# WKUP_CTRL_MMR_WKUP_CTRL_MMR_CFG0_43000000h register map
Vendor: Texas Instruments
Peripheral module from a debugger description file (folder am62D).
Registers are 32-bit, read-write, reset 0x0 unless marked. A register's access mark holds for its fields unless they carry their own. Offsets are as the file gives them; lines under a group give offsets from that group; [hi:lo] are bit positions; {n}, {i} and the like mark numbered series; 'fields as' and 'values as' point back to an identical list; <NAME> marks a mode.

## WKUP_CTRL_MMR_CFG0 (part 1 of 3)
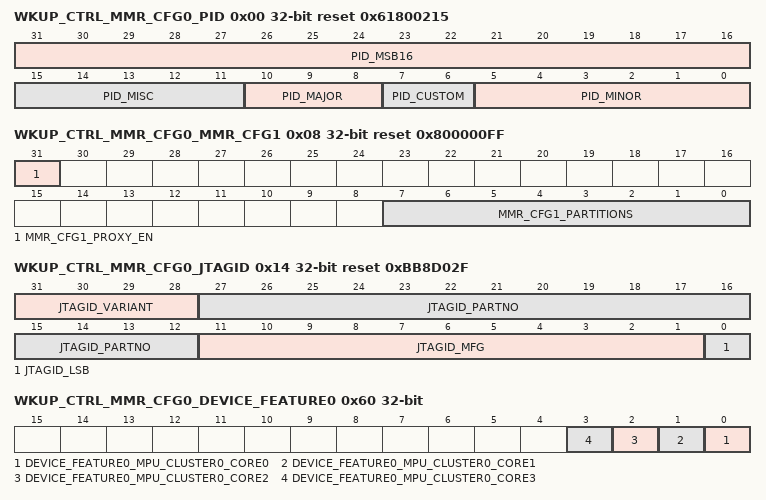
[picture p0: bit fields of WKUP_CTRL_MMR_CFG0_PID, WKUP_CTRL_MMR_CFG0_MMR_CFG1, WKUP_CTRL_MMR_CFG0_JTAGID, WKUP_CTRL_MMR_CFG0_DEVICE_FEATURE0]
0x00 WKUP_CTRL_MMR_CFG0_PID ro reset 0x61800215
  [31:16] PID_MSB16 — Reset Source: mod_g_rst_n
  [15:11] PID_MISC — Reset Source: mod_g_rst_n
  [10:8] PID_MAJOR — Reset Source: mod_g_rst_n
  [7:6] PID_CUSTOM — Reset Source: mod_g_rst_n
  [5:0] PID_MINOR — Reset Source: mod_g_rst_n
0x08 WKUP_CTRL_MMR_CFG0_MMR_CFG1 ro reset 0x800000FF
  [31] MMR_CFG1_PROXY_EN — Proxy addressing activated Reset Source: mod_por_rst_n
  [7:0] MMR_CFG1_PARTITIONS — Indicates present partitions Reset Source: mod_por_rst_n
0x14 WKUP_CTRL_MMR_CFG0_JTAGID ro reset 0xBB8D02F
  [31:28] JTAGID_VARIANT — Used to indicate new PGs Reset Source: mod_por_rst_n
  [27:12] JTAGID_PARTNO — Part number for boundary scan Reset Source: mod_por_rst_n
  [11:1] JTAGID_MFG — Indicates manufacturer Reset Source: mod_por_rst_n
  [0] JTAGID_LSB — Always 1 Reset Source: mod_por_rst_n
0x18 WKUP_CTRL_MMR_CFG0_JTAG_USER_ID ro
  [31:0] JTAG_USER_ID_USERCODE — Device information Reset Source: mod_por_rst_n
0x30 WKUP_CTRL_MMR_CFG0_MAIN_DEVSTAT
  [15:0] MAIN_DEVSTAT_BOOTMODE — Specifies the device Primary and Backup boot media. Reset Source: mod_por_rst_n
0x34 WKUP_CTRL_MMR_CFG0_MAIN_BOOTCFG ro
  [15:0] MAIN_BOOTCFG_BOOTMODE — Specifies the device Primary and Backup boot media as latched at PORz Reset Source: mod_por_rst_n
0x44 WKUP_CTRL_MMR_CFG0_BOOT_PROGRESS
  [31:0] BOOT_PROGRESS_PROGRESS — Written by ROM to indicate boot progression. Values and their meaning are determined by the ROM. Reset Source: mod_por_rst_n
0x60 WKUP_CTRL_MMR_CFG0_DEVICE_FEATURE0 ro
  [n] DEVICE_FEATURE0_MPU_CLUSTER0_CORE{n} (n=0..3) — MPU Cluster0 Core {n} is activated when set Reset Source: mod_por_rst_n
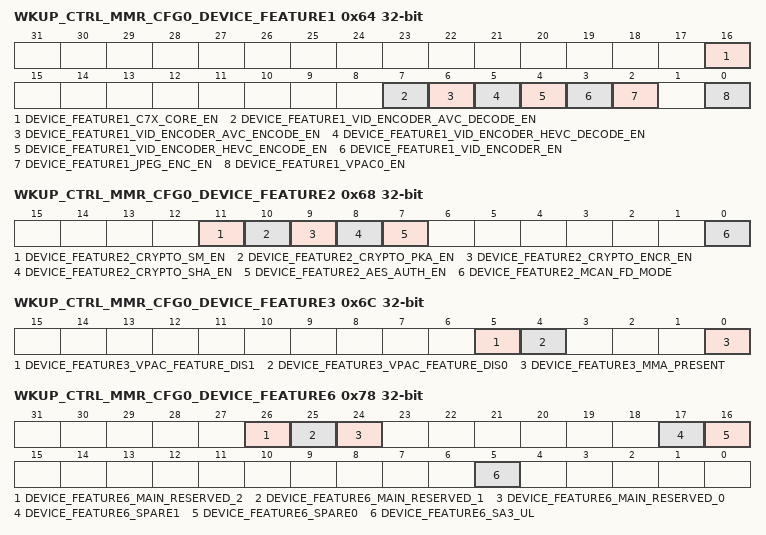
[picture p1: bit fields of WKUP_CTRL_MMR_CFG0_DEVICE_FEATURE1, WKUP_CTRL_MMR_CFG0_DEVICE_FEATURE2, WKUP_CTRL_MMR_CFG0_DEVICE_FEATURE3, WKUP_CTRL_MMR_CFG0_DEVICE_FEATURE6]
0x64 WKUP_CTRL_MMR_CFG0_DEVICE_FEATURE1 ro
  [16] DEVICE_FEATURE1_C7X_CORE_EN — C7x is activated when set Reset Source: mod_por_rst_n
  [7] DEVICE_FEATURE1_VID_ENCODER_AVC_DECODE_EN — Video CODEC HEVC decode feature activated when set Reset Source: mod_por_rst_n
  [6] DEVICE_FEATURE1_VID_ENCODER_AVC_ENCODE_EN — Video CODEC HEVC encode feature activated when set Reset Source: mod_por_rst_n
  [5] DEVICE_FEATURE1_VID_ENCODER_HEVC_DECODE_EN — Video CODEC AVC decode feature activated when set Reset Source: mod_por_rst_n
  [4] DEVICE_FEATURE1_VID_ENCODER_HEVC_ENCODE_EN — Video CODEC AVC encode feature activated when set Reset Source: mod_por_rst_n
  [3] DEVICE_FEATURE1_VID_ENCODER_EN — Video CODEC is activated when set Reset Source: mod_por_rst_n
  [2] DEVICE_FEATURE1_JPEG_ENC_EN — JPEG Encoder is activated when set Reset Source: mod_por_rst_n
  [0] DEVICE_FEATURE1_VPAC0_EN — VPAC0 is activated when set Reset Source: mod_por_rst_n
0x68 WKUP_CTRL_MMR_CFG0_DEVICE_FEATURE2 ro
  [11] DEVICE_FEATURE2_CRYPTO_SM_EN — SA3SS Crypto Module SM2, SM3, SM4 activated Reset Source: mod_por_rst_n
  [10] DEVICE_FEATURE2_CRYPTO_PKA_EN — SA3SS Crypto Module PKA activated Reset Source: mod_por_rst_n
  [9] DEVICE_FEATURE2_CRYPTO_ENCR_EN — SA3SS Crypto Module AES/3DES/DBRG activated Reset Source: mod_por_rst_n
  [8] DEVICE_FEATURE2_CRYPTO_SHA_EN — SA3SS Crypto Module SHA/MD5 activated Reset Source: mod_por_rst_n
  [7] DEVICE_FEATURE2_AES_AUTH_EN — AES authentication is activated in FlashSS and SMS when set Reset Source: mod_por_rst_n
  [0] DEVICE_FEATURE2_MCAN_FD_MODE — FD mode is supported on all MCAN when set Reset Source: mod_por_rst_n
0x6C WKUP_CTRL_MMR_CFG0_DEVICE_FEATURE3 ro
  [5] DEVICE_FEATURE3_VPAC_FEATURE_DIS1 — VPAC Feature 1 Deactivated When Set Reset Source: mod_por_rst_n
  [4] DEVICE_FEATURE3_VPAC_FEATURE_DIS0 — VPAC Feature 0 DIsabled When Set Reset Source: mod_por_rst_n
  [0] DEVICE_FEATURE3_MMA_PRESENT — C7x MMA Present when Set Reset Source: mod_por_rst_n
0x78 WKUP_CTRL_MMR_CFG0_DEVICE_FEATURE6 ro
  [26] DEVICE_FEATURE6_MAIN_RESERVED_2 — Main Domain Reserved 2 LPSC is activated when set
  [25] DEVICE_FEATURE6_MAIN_RESERVED_1 — Main Domain Reserved 1 LPSC is activated when set
  [24] DEVICE_FEATURE6_MAIN_RESERVED_0 — Main Domain Reserved 0 LPSC is activated when set
  [17] DEVICE_FEATURE6_SPARE1 — Spare1 LPSC is activated when set Reset Source: mod_por_rst_n
  [16] DEVICE_FEATURE6_SPARE0 — Spare0 LPSC is activated when set Reset Source: mod_por_rst_n
  [5] DEVICE_FEATURE6_SA3_UL — SA3SS domain security accelerator is activated when set Reset Source: mod_por_rst_n
0x200 WKUP_CTRL_MMR_CFG0_MAC_ID0
  [31:0] MAC_ID0_MACID_LO — 32 lsbs of MAC address Reset Source: mod_g_rst_n
0x204 WKUP_CTRL_MMR_CFG0_MAC_ID1
  [15:0] MAC_ID1_MACID_HI — 16 msbs of MAC address Reset Source: mod_g_rst_n
0x220 WKUP_CTRL_MMR_CFG0_USB_DEVICE_ID0 reset 0x61650451
  [31:0] USB_DEVICE_ID0_ID0 — ROM writes 32-bit Value from Customer OTP to Here Reset Source: mod_g_rst_n
0x224 WKUP_CTRL_MMR_CFG0_USB_DEVICE_ID1 reset 0x61650451
  [31:0] USB_DEVICE_ID1_ID1 — ROM writes 32-bit Value from Customer OTP to Here Reset Source: mod_g_rst_n
{0x230+4i} WKUP_CTRL_MMR_CFG0_GP_SW{i} ro (i=0..2)
  [31:0] GP_SW{i}_VAL — general purpose value Reset Source: mod_por_rst_n
0x23C WKUP_CTRL_MMR_CFG0_GP_SW3 ro
  [3:0] GP_SW3_VAL — general purpose value Reset Source: mod_por_rst_n
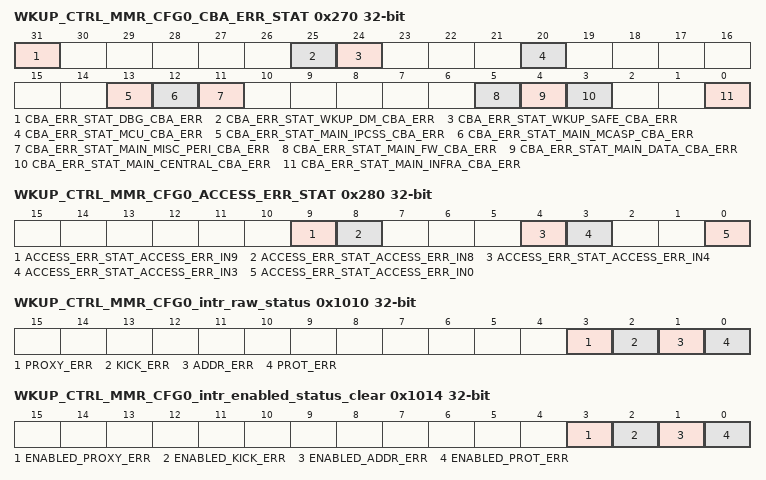
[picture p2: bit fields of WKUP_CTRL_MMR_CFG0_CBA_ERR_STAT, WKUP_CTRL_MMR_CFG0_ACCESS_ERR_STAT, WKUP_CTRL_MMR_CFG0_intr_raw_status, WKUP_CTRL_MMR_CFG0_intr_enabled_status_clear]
0x270 WKUP_CTRL_MMR_CFG0_CBA_ERR_STAT ro
  [31] CBA_ERR_STAT_DBG_CBA_ERR — Access Error from Main Debug CBASS Reset Source: mod_g_rst_n
  [25] CBA_ERR_STAT_WKUP_DM_CBA_ERR — Access Error from Wkup Device Manager CBASS Reset Source: mod_g_rst_n
  [24] CBA_ERR_STAT_WKUP_SAFE_CBA_ERR — Access Error from Wkup Safe CBASS Reset Source: mod_g_rst_n
  [20] CBA_ERR_STAT_MCU_CBA_ERR — Access Error from MCU CBASS Reset Source: mod_g_rst_n
  [13] CBA_ERR_STAT_MAIN_IPCSS_CBA_ERR — Access Error from Main IPCSS CBASS Reset Source: mod_g_rst_n
  [12] CBA_ERR_STAT_MAIN_MCASP_CBA_ERR — Access Error from Main McASP CBASS Reset Source: mod_g_rst_n
  [11] CBA_ERR_STAT_MAIN_MISC_PERI_CBA_ERR — Access Errror from Main Misc. Peripheral CBASS Reset Source: mod_g_rst_n
  [5] CBA_ERR_STAT_MAIN_FW_CBA_ERR — Access Error from Main Firewall CBASS Reset Source: mod_g_rst_n
  [4] CBA_ERR_STAT_MAIN_DATA_CBA_ERR — Access Error from Main Data CBASS Reset Source: mod_g_rst_n
  [3] CBA_ERR_STAT_MAIN_CENTRAL_CBA_ERR — Access Error from Main Central CBASS Reset Source: mod_g_rst_n
  [0] CBA_ERR_STAT_MAIN_INFRA_CBA_ERR — Access Error from Main Infrastructure CBASS Reset Source: mod_g_rst_n
0x280 WKUP_CTRL_MMR_CFG0_ACCESS_ERR_STAT ro
  [9] ACCESS_ERR_STAT_ACCESS_ERR_IN9 — Access Error Detected in MCU PadCfg MMR Reset Source: mod_por_rst_n
  [8] ACCESS_ERR_STAT_ACCESS_ERR_IN8 — Access Error Detected in MCU Ctrl MMR Reset Source: mod_por_rst_n
  [4] ACCESS_ERR_STAT_ACCESS_ERR_IN4 — Access Error Detected in MAIN PadCfg MMR Reset Source: mod_por_rst_n
  [3] ACCESS_ERR_STAT_ACCESS_ERR_IN3 — Access Error Detected in MAIN Ctrl MMR Reset Source: mod_por_rst_n
  [0] ACCESS_ERR_STAT_ACCESS_ERR_IN0 — Access Error Detected in WKUP Ctrl MMR Reset Source: mod_por_rst_n
{0x1008+0x4000*i} WKUP_CTRL_MMR_CFG0_LOCK{i}_KICK0 (i=0..7)
  [31:0] LOCK{i}_KICK0 — - KICK0 component Reset Source: mod_g_rst_n
{0x100C+0x4000*i} WKUP_CTRL_MMR_CFG0_LOCK{i}_KICK1 (i=0..7)
  [31:0] LOCK{i}_KICK1 — - KICK1 component Reset Source: mod_g_rst_n
0x1010 WKUP_CTRL_MMR_CFG0_intr_raw_status access not given
  [3] PROXY_ERR — Proxy0 access violation error. Raw status is read. Write a 1 to set the status. Writing a 0 has no effect. Reset Source: mod_g_rst_n (access R/W1TS)
  [2] KICK_ERR — Kick access violation error. Raw status is read. Write a 1 to set the status. Writing a 0 has no effect. Reset Source: mod_g_rst_n (access R/W1TS)
  [1] ADDR_ERR — Addressing violation error. Raw status is read. Write a 1 to set the status. Writing a 0 has no effect. Reset Source: mod_g_rst_n (access R/W1TS)
  [0] PROT_ERR — Protection violation error. Raw status is read. Write a 1 to set the status. Writing a 0 has no effect. Reset Source: mod_g_rst_n (access R/W1TS)
0x1014 WKUP_CTRL_MMR_CFG0_intr_enabled_status_clear access not given
  [3] ENABLED_PROXY_ERR — Proxy0 access violation error. Enabled status is read. Write a 1 to clear the status. Writing a 0 has no effect. Reset Source: mod_g_rst_n (access R/W1TC)
  [2] ENABLED_KICK_ERR — Kick access violation error. Enabled status is read. Write a 1 to clear the status. Writing a 0 has no effect. Reset Source: mod_g_rst_n (access R/W1TC)
  [1] ENABLED_ADDR_ERR — Addressing violation error. Enabled status is read. Write a 1 to clear the status. Writing a 0 has no effect. Reset Source: mod_g_rst_n (access R/W1TC)
  [0] ENABLED_PROT_ERR — Protection violation error. Enabled status is read. Write a 1 to clear the status. Writing a 0 has no effect. Reset Source: mod_g_rst_n (access R/W1TC)
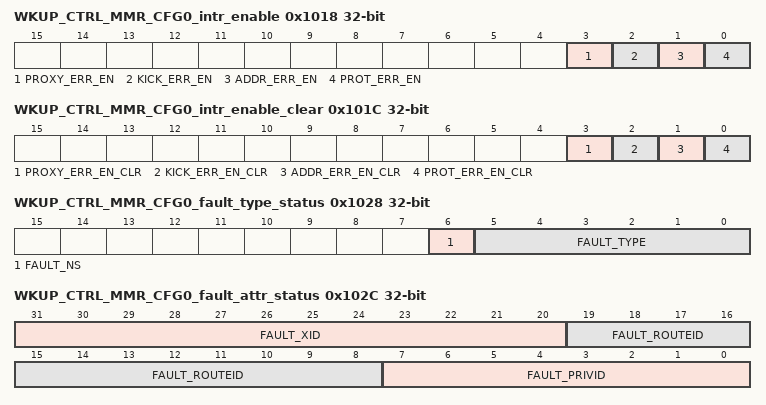
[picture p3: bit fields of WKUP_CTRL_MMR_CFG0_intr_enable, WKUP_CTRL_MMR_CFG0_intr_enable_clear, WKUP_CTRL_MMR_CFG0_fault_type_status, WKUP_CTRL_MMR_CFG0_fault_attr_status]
0x1018 WKUP_CTRL_MMR_CFG0_intr_enable access not given
  [3] PROXY_ERR_EN — Proxy0 access violation error enable. Write a 1 to set the enable. Writing a 0 has no effect. Reset Source: mod_g_rst_n (access R/W1TS)
  [2] KICK_ERR_EN — Kick access violation error enable. Write a 1 to set the enable. Writing a 0 has no effect. Reset Source: mod_g_rst_n (access R/W1TS)
  [1] ADDR_ERR_EN — Addressing violation error enable. Write a 1 to set the enable. Writing a 0 has no effect. Reset Source: mod_g_rst_n (access R/W1TS)
  [0] PROT_ERR_EN — Protection violation error enable. Write a 1 to set the enable. Writing a 0 has no effect. Reset Source: mod_g_rst_n (access R/W1TS)
0x101C WKUP_CTRL_MMR_CFG0_intr_enable_clear access not given
  [3] PROXY_ERR_EN_CLR — Proxy0 access violation error enable clear. Write a 1 to clear the enable. Writing a 0 has no effect. Reset Source: mod_g_rst_n (access R/W1TC)
  [2] KICK_ERR_EN_CLR — Kick access violation error enable clear. Write a 1 to clear the enable. Writing a 0 has no effect. Reset Source: mod_g_rst_n (access R/W1TC)
  [1] ADDR_ERR_EN_CLR — Addressing violation error enable clear. Write a 1 to clear the enable. Writing a 0 has no effect. Reset Source: mod_g_rst_n (access R/W1TC)
  [0] PROT_ERR_EN_CLR — Protection violation error enable clear. Write a 1 to clear the enable. Writing a 0 has no effect. Reset Source: mod_g_rst_n (access R/W1TC)
0x1020 WKUP_CTRL_MMR_CFG0_eoi
  [7:0] EOI_VECTOR — EOI vector value. Write this with interrupt distribution value in the chip. Reset Source: mod_g_rst_n
0x1024 WKUP_CTRL_MMR_CFG0_fault_address ro
  [31:0] FAULT_ADDR — Fault Address. Reset Source: mod_g_rst_n
0x1028 WKUP_CTRL_MMR_CFG0_fault_type_status ro
  [6] FAULT_NS — Non-secure access. Reset Source: mod_g_rst_n
  [5:0] FAULT_TYPE — Fault Type 10_0000 = Supervisor read fault - priv = 1 dir = 1 dtype != 1 01_0000 = Supervisor write fault - priv = 1 dir = 0 00_1000 = Supervisor execute fault - priv = 1 dir = 1 dtype = 1 00_0100 = User read fault - priv = 0 dir = 1 dtype = 1 00_0010 = User write fault - priv = 0 dir = 0 00_0001 = User execute fault - priv = 0 dir = 1 dtype = 1 00_0000 = No fault Reset Source: mod_g_rst_n
0x102C WKUP_CTRL_MMR_CFG0_fault_attr_status ro
  [31:20] FAULT_XID — XID. Reset Source: mod_g_rst_n
  [19:8] FAULT_ROUTEID — Route ID. Reset Source: mod_g_rst_n
  [7:0] FAULT_PRIVID — Privilege ID. Reset Source: mod_g_rst_n
0x1030 WKUP_CTRL_MMR_CFG0_fault_clear wo
  [0] FAULT_CLR — Fault clear. Writing a 1 clears the current fault. Writing a 0 has no effect. Reset Source: mod_g_rst_n
{0x1100+4i} WKUP_CTRL_MMR_CFG0_CLAIMREG_P0_R{i}_READONLY ro (i=0..6)
  [31:0] CLAIMREG_P0_R{i}_READONLY — Claim bits for Partition 0 Reset Source: mod_g_rst_n
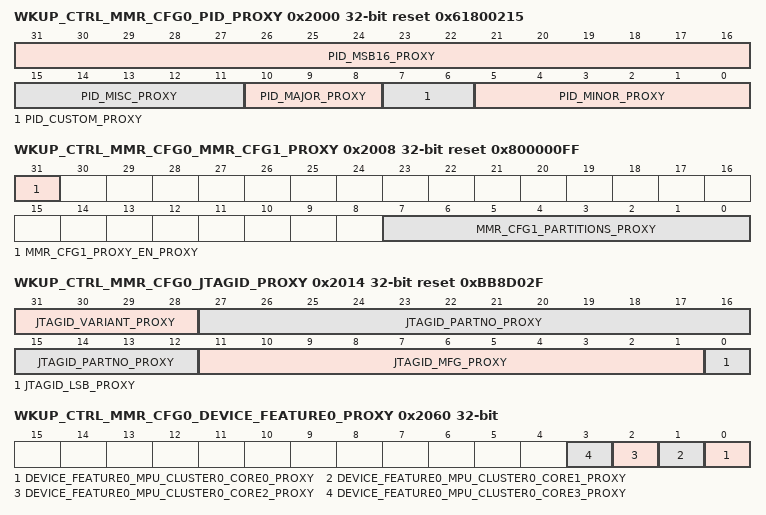
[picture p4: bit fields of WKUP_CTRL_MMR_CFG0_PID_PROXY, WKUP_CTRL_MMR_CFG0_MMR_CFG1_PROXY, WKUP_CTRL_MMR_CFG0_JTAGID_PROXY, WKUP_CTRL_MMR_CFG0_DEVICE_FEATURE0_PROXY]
0x2000 WKUP_CTRL_MMR_CFG0_PID_PROXY ro reset 0x61800215
  [31:16] PID_MSB16_PROXY — Reset Source: mod_g_rst_n
  [15:11] PID_MISC_PROXY — Reset Source: mod_g_rst_n
  [10:8] PID_MAJOR_PROXY — Reset Source: mod_g_rst_n
  [7:6] PID_CUSTOM_PROXY — Reset Source: mod_g_rst_n
  [5:0] PID_MINOR_PROXY — Reset Source: mod_g_rst_n
0x2008 WKUP_CTRL_MMR_CFG0_MMR_CFG1_PROXY ro reset 0x800000FF
  [31] MMR_CFG1_PROXY_EN_PROXY — Proxy addressing activated Reset Source: mod_por_rst_n
  [7:0] MMR_CFG1_PARTITIONS_PROXY — Indicates present partitions Reset Source: mod_por_rst_n
0x2014 WKUP_CTRL_MMR_CFG0_JTAGID_PROXY ro reset 0xBB8D02F
  [31:28] JTAGID_VARIANT_PROXY — Used to indicate new PGs Reset Source: mod_por_rst_n
  [27:12] JTAGID_PARTNO_PROXY — Part number for boundary scan Reset Source: mod_por_rst_n
  [11:1] JTAGID_MFG_PROXY — Indicates manufacturer Reset Source: mod_por_rst_n
  [0] JTAGID_LSB_PROXY — Always 1 Reset Source: mod_por_rst_n
0x2018 WKUP_CTRL_MMR_CFG0_JTAG_USER_ID_PROXY ro
  [31:0] JTAG_USER_ID_USERCODE_PROXY — Device information Reset Source: mod_por_rst_n
0x2030 WKUP_CTRL_MMR_CFG0_MAIN_DEVSTAT_PROXY
  [15:0] MAIN_DEVSTAT_BOOTMODE_PROXY — Specifies the device Primary and Backup boot media. Reset Source: mod_por_rst_n
0x2034 WKUP_CTRL_MMR_CFG0_MAIN_BOOTCFG_PROXY ro
  [15:0] MAIN_BOOTCFG_BOOTMODE_PROXY — Specifies the device Primary and Backup boot media as latched at PORz Reset Source: mod_por_rst_n
0x2044 WKUP_CTRL_MMR_CFG0_BOOT_PROGRESS_PROXY
  [31:0] BOOT_PROGRESS_PROGRESS_PROXY — Written by ROM to indicate boot progression. Values and their meaning are determined by the ROM. Reset Source: mod_por_rst_n
0x2060 WKUP_CTRL_MMR_CFG0_DEVICE_FEATURE0_PROXY ro
  [n] DEVICE_FEATURE0_MPU_CLUSTER0_CORE{n}_PROXY (n=0..3) — MPU Cluster0 Core {n} is activated when set Reset Source: mod_por_rst_n
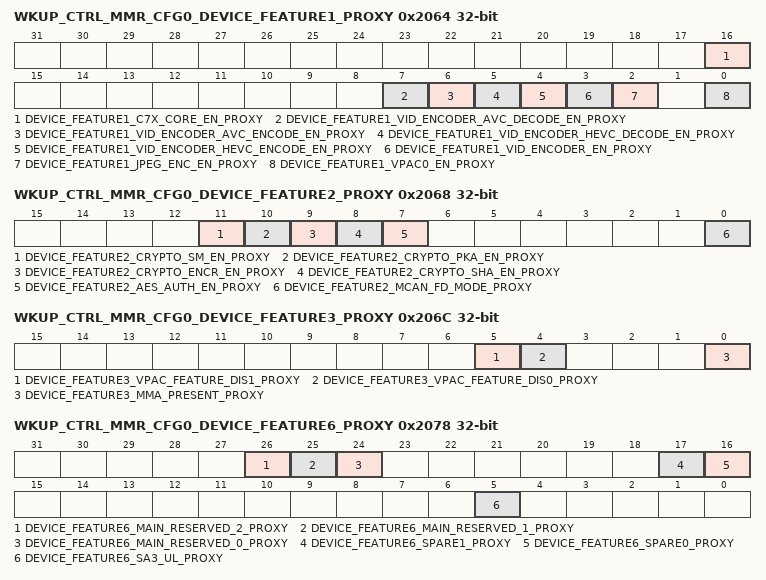
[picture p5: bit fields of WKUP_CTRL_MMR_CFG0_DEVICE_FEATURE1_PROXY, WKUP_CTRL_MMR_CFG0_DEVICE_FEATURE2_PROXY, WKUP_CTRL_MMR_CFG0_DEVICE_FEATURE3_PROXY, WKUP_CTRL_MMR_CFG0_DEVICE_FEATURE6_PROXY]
0x2064 WKUP_CTRL_MMR_CFG0_DEVICE_FEATURE1_PROXY ro
  [16] DEVICE_FEATURE1_C7X_CORE_EN_PROXY — C7x is activated when set Reset Source: mod_por_rst_n
  [7] DEVICE_FEATURE1_VID_ENCODER_AVC_DECODE_EN_PROXY — Video CODEC HEVC decode feature activated when set Reset Source: mod_por_rst_n
  [6] DEVICE_FEATURE1_VID_ENCODER_AVC_ENCODE_EN_PROXY — Video CODEC HEVC encode feature activated when set Reset Source: mod_por_rst_n
  [5] DEVICE_FEATURE1_VID_ENCODER_HEVC_DECODE_EN_PROXY — Video CODEC AVC decode feature activated when set Reset Source: mod_por_rst_n
  [4] DEVICE_FEATURE1_VID_ENCODER_HEVC_ENCODE_EN_PROXY — Video CODEC AVC encode feature activated when set Reset Source: mod_por_rst_n
  [3] DEVICE_FEATURE1_VID_ENCODER_EN_PROXY — Video CODEC is activated when set Reset Source: mod_por_rst_n
  [2] DEVICE_FEATURE1_JPEG_ENC_EN_PROXY — JPEG Encoder is activated when set Reset Source: mod_por_rst_n
  [0] DEVICE_FEATURE1_VPAC0_EN_PROXY — VPAC0 is activated when set Reset Source: mod_por_rst_n
0x2068 WKUP_CTRL_MMR_CFG0_DEVICE_FEATURE2_PROXY ro
  [11] DEVICE_FEATURE2_CRYPTO_SM_EN_PROXY — SA3SS Crypto Module SM2, SM3, SM4 activated Reset Source: mod_por_rst_n
  [10] DEVICE_FEATURE2_CRYPTO_PKA_EN_PROXY — SA3SS Crypto Module PKA activated Reset Source: mod_por_rst_n
  [9] DEVICE_FEATURE2_CRYPTO_ENCR_EN_PROXY — SA3SS Crypto Module AES/3DES/DBRG activated Reset Source: mod_por_rst_n
  [8] DEVICE_FEATURE2_CRYPTO_SHA_EN_PROXY — SA3SS Crypto Module SHA/MD5 activated Reset Source: mod_por_rst_n
  [7] DEVICE_FEATURE2_AES_AUTH_EN_PROXY — AES authentication is activated in FlashSS and SMS when set Reset Source: mod_por_rst_n
  [0] DEVICE_FEATURE2_MCAN_FD_MODE_PROXY — FD mode is supported on all MCAN when set Reset Source: mod_por_rst_n
0x206C WKUP_CTRL_MMR_CFG0_DEVICE_FEATURE3_PROXY ro
  [5] DEVICE_FEATURE3_VPAC_FEATURE_DIS1_PROXY — VPAC Feature 1 Deactivated When Set Reset Source: mod_por_rst_n
  [4] DEVICE_FEATURE3_VPAC_FEATURE_DIS0_PROXY — VPAC Feature 0 DIsabled When Set Reset Source: mod_por_rst_n
  [0] DEVICE_FEATURE3_MMA_PRESENT_PROXY — C7x MMA Present when Set Reset Source: mod_por_rst_n
0x2078 WKUP_CTRL_MMR_CFG0_DEVICE_FEATURE6_PROXY ro
  [26] DEVICE_FEATURE6_MAIN_RESERVED_2_PROXY — Main Domain Reserved 2 LPSC is activated when set
  [25] DEVICE_FEATURE6_MAIN_RESERVED_1_PROXY — Main Domain Reserved 1 LPSC is activated when set
  [24] DEVICE_FEATURE6_MAIN_RESERVED_0_PROXY — Main Domain Reserved 0 LPSC is activated when set
  [17] DEVICE_FEATURE6_SPARE1_PROXY — Spare1 LPSC is activated when set Reset Source: mod_por_rst_n
  [16] DEVICE_FEATURE6_SPARE0_PROXY — Spare0 LPSC is activated when set Reset Source: mod_por_rst_n
  [5] DEVICE_FEATURE6_SA3_UL_PROXY — SA3SS domain security accelerator is activated when set Reset Source: mod_por_rst_n
0x2200 WKUP_CTRL_MMR_CFG0_MAC_ID0_PROXY
  [31:0] MAC_ID0_MACID_LO_PROXY — 32 lsbs of MAC address Reset Source: mod_g_rst_n
0x2204 WKUP_CTRL_MMR_CFG0_MAC_ID1_PROXY
  [15:0] MAC_ID1_MACID_HI_PROXY — 16 msbs of MAC address Reset Source: mod_g_rst_n
0x2220 WKUP_CTRL_MMR_CFG0_USB_DEVICE_ID0_PROXY reset 0x61650451
  [31:0] USB_DEVICE_ID0_ID0_PROXY — ROM writes 32-bit Value from Customer OTP to Here Reset Source: mod_g_rst_n
0x2224 WKUP_CTRL_MMR_CFG0_USB_DEVICE_ID1_PROXY reset 0x61650451
  [31:0] USB_DEVICE_ID1_ID1_PROXY — ROM writes 32-bit Value from Customer OTP to Here Reset Source: mod_g_rst_n
{0x2230+4i} WKUP_CTRL_MMR_CFG0_GP_SW{i}_PROXY ro (i=0..2)
  [31:0] GP_SW{i}_VAL_PROXY — general purpose value Reset Source: mod_por_rst_n
0x223C WKUP_CTRL_MMR_CFG0_GP_SW3_PROXY ro
  [3:0] GP_SW3_VAL_PROXY — general purpose value Reset Source: mod_por_rst_n
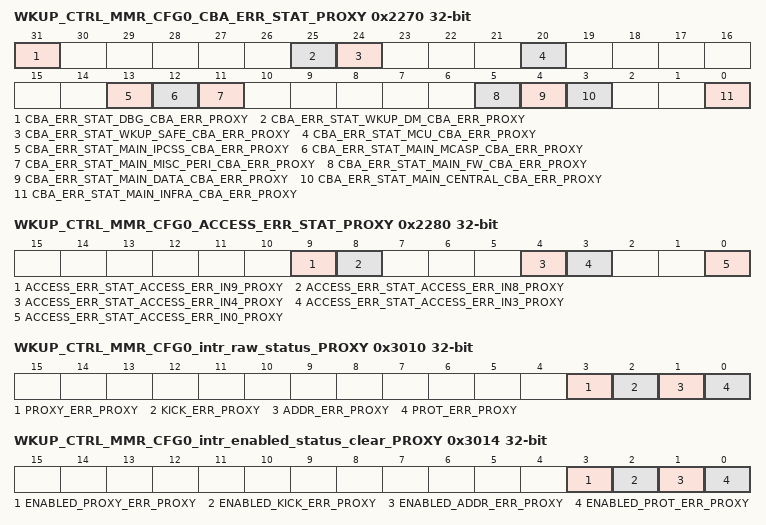
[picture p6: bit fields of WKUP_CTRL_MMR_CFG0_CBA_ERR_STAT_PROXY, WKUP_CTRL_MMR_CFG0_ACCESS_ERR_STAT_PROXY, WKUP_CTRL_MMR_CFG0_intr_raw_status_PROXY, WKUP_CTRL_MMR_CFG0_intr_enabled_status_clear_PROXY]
0x2270 WKUP_CTRL_MMR_CFG0_CBA_ERR_STAT_PROXY ro
  [31] CBA_ERR_STAT_DBG_CBA_ERR_PROXY — Access Error from Main Debug CBASS Reset Source: mod_g_rst_n
  [25] CBA_ERR_STAT_WKUP_DM_CBA_ERR_PROXY — Access Error from Wkup Device Manager CBASS Reset Source: mod_g_rst_n
  [24] CBA_ERR_STAT_WKUP_SAFE_CBA_ERR_PROXY — Access Error from Wkup Safe CBASS Reset Source: mod_g_rst_n
  [20] CBA_ERR_STAT_MCU_CBA_ERR_PROXY — Access Error from MCU CBASS Reset Source: mod_g_rst_n
  [13] CBA_ERR_STAT_MAIN_IPCSS_CBA_ERR_PROXY — Access Error from Main IPCSS CBASS Reset Source: mod_g_rst_n
  [12] CBA_ERR_STAT_MAIN_MCASP_CBA_ERR_PROXY — Access Error from Main McASP CBASS Reset Source: mod_g_rst_n
  [11] CBA_ERR_STAT_MAIN_MISC_PERI_CBA_ERR_PROXY — Access Errror from Main Misc. Peripheral CBASS Reset Source: mod_g_rst_n
  [5] CBA_ERR_STAT_MAIN_FW_CBA_ERR_PROXY — Access Error from Main Firewall CBASS Reset Source: mod_g_rst_n
  [4] CBA_ERR_STAT_MAIN_DATA_CBA_ERR_PROXY — Access Error from Main Data CBASS Reset Source: mod_g_rst_n
  [3] CBA_ERR_STAT_MAIN_CENTRAL_CBA_ERR_PROXY — Access Error from Main Central CBASS Reset Source: mod_g_rst_n
  [0] CBA_ERR_STAT_MAIN_INFRA_CBA_ERR_PROXY — Access Error from Main Infrastructure CBASS Reset Source: mod_g_rst_n
0x2280 WKUP_CTRL_MMR_CFG0_ACCESS_ERR_STAT_PROXY ro
  [9] ACCESS_ERR_STAT_ACCESS_ERR_IN9_PROXY — Access Error Detected in MCU PadCfg MMR Reset Source: mod_por_rst_n
  [8] ACCESS_ERR_STAT_ACCESS_ERR_IN8_PROXY — Access Error Detected in MCU Ctrl MMR Reset Source: mod_por_rst_n
  [4] ACCESS_ERR_STAT_ACCESS_ERR_IN4_PROXY — Access Error Detected in MAIN PadCfg MMR Reset Source: mod_por_rst_n
  [3] ACCESS_ERR_STAT_ACCESS_ERR_IN3_PROXY — Access Error Detected in MAIN Ctrl MMR Reset Source: mod_por_rst_n
  [0] ACCESS_ERR_STAT_ACCESS_ERR_IN0_PROXY — Access Error Detected in WKUP Ctrl MMR Reset Source: mod_por_rst_n
{0x3008+0x4000*i} WKUP_CTRL_MMR_CFG0_LOCK{i}_KICK0_PROXY (i=0..7)
  [31:0] LOCK{i}_KICK0_PROXY — - KICK0 component Reset Source: mod_g_rst_n
{0x300C+0x4000*i} WKUP_CTRL_MMR_CFG0_LOCK{i}_KICK1_PROXY (i=0..7)
  [31:0] LOCK{i}_KICK1_PROXY — - KICK1 component Reset Source: mod_g_rst_n
0x3010 WKUP_CTRL_MMR_CFG0_intr_raw_status_PROXY access not given
  [3] PROXY_ERR_PROXY — Proxy0 access violation error. Raw status is read. Write a 1 to set the status. Writing a 0 has no effect. Reset Source: mod_g_rst_n (access R/W1TS)
  [2] KICK_ERR_PROXY — Kick access violation error. Raw status is read. Write a 1 to set the status. Writing a 0 has no effect. Reset Source: mod_g_rst_n (access R/W1TS)
  [1] ADDR_ERR_PROXY — Addressing violation error. Raw status is read. Write a 1 to set the status. Writing a 0 has no effect. Reset Source: mod_g_rst_n (access R/W1TS)
  [0] PROT_ERR_PROXY — Protection violation error. Raw status is read. Write a 1 to set the status. Writing a 0 has no effect. Reset Source: mod_g_rst_n (access R/W1TS)
0x3014 WKUP_CTRL_MMR_CFG0_intr_enabled_status_clear_PROXY access not given
  [3] ENABLED_PROXY_ERR_PROXY — Proxy0 access violation error. Enabled status is read. Write a 1 to clear the status. Writing a 0 has no effect. Reset Source: mod_g_rst_n (access R/W1TC)
  [2] ENABLED_KICK_ERR_PROXY — Kick access violation error. Enabled status is read. Write a 1 to clear the status. Writing a 0 has no effect. Reset Source: mod_g_rst_n (access R/W1TC)
  [1] ENABLED_ADDR_ERR_PROXY — Addressing violation error. Enabled status is read. Write a 1 to clear the status. Writing a 0 has no effect. Reset Source: mod_g_rst_n (access R/W1TC)
  [0] ENABLED_PROT_ERR_PROXY — Protection violation error. Enabled status is read. Write a 1 to clear the status. Writing a 0 has no effect. Reset Source: mod_g_rst_n (access R/W1TC)
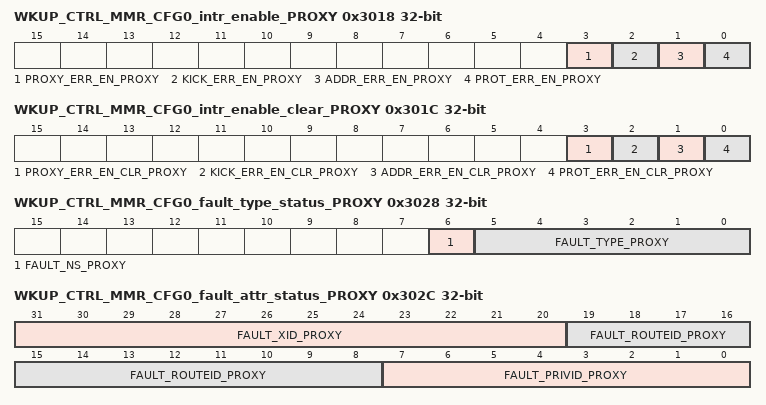
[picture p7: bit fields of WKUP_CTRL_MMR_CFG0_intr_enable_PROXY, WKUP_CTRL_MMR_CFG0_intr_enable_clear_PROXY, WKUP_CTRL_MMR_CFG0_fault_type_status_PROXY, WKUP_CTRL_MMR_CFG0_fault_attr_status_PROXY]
0x3018 WKUP_CTRL_MMR_CFG0_intr_enable_PROXY access not given
  [3] PROXY_ERR_EN_PROXY — Proxy0 access violation error enable. Write a 1 to set the enable. Writing a 0 has no effect. Reset Source: mod_g_rst_n (access R/W1TS)
  [2] KICK_ERR_EN_PROXY — Kick access violation error enable. Write a 1 to set the enable. Writing a 0 has no effect. Reset Source: mod_g_rst_n (access R/W1TS)
  [1] ADDR_ERR_EN_PROXY — Addressing violation error enable. Write a 1 to set the enable. Writing a 0 has no effect. Reset Source: mod_g_rst_n (access R/W1TS)
  [0] PROT_ERR_EN_PROXY — Protection violation error enable. Write a 1 to set the enable. Writing a 0 has no effect. Reset Source: mod_g_rst_n (access R/W1TS)
0x301C WKUP_CTRL_MMR_CFG0_intr_enable_clear_PROXY access not given
  [3] PROXY_ERR_EN_CLR_PROXY — Proxy0 access violation error enable clear. Write a 1 to clear the enable. Writing a 0 has no effect. Reset Source: mod_g_rst_n (access R/W1TC)
  [2] KICK_ERR_EN_CLR_PROXY — Kick access violation error enable clear. Write a 1 to clear the enable. Writing a 0 has no effect. Reset Source: mod_g_rst_n (access R/W1TC)
  [1] ADDR_ERR_EN_CLR_PROXY — Addressing violation error enable clear. Write a 1 to clear the enable. Writing a 0 has no effect. Reset Source: mod_g_rst_n (access R/W1TC)
  [0] PROT_ERR_EN_CLR_PROXY — Protection violation error enable clear. Write a 1 to clear the enable. Writing a 0 has no effect. Reset Source: mod_g_rst_n (access R/W1TC)
0x3020 WKUP_CTRL_MMR_CFG0_eoi_PROXY
  [7:0] EOI_VECTOR_PROXY — EOI vector value. Write this with interrupt distribution value in the chip. Reset Source: mod_g_rst_n
0x3024 WKUP_CTRL_MMR_CFG0_fault_address_PROXY ro
  [31:0] FAULT_ADDR_PROXY — Fault Address. Reset Source: mod_g_rst_n
0x3028 WKUP_CTRL_MMR_CFG0_fault_type_status_PROXY ro
  [6] FAULT_NS_PROXY — Non-secure access. Reset Source: mod_g_rst_n
  [5:0] FAULT_TYPE_PROXY — Fault Type 10_0000 = Supervisor read fault - priv = 1 dir = 1 dtype != 1 01_0000 = Supervisor write fault - priv = 1 dir = 0 00_1000 = Supervisor execute fault - priv = 1 dir = 1 dtype = 1 00_0100 = User read fault - priv = 0 dir = 1 dtype = 1 00_0010 = User write fault - priv = 0 dir = 0 00_0001 = User execute fault - priv = 0 dir = 1 dtype = 1 00_0000 = No fault Reset Source: mod_g_rst_n
0x302C WKUP_CTRL_MMR_CFG0_fault_attr_status_PROXY ro
  [31:20] FAULT_XID_PROXY — XID. Reset Source: mod_g_rst_n
  [19:8] FAULT_ROUTEID_PROXY — Route ID. Reset Source: mod_g_rst_n
  [7:0] FAULT_PRIVID_PROXY — Privilege ID. Reset Source: mod_g_rst_n
0x3030 WKUP_CTRL_MMR_CFG0_fault_clear_PROXY wo
  [0] FAULT_CLR_PROXY — Fault clear. Writing a 1 clears the current fault. Writing a 0 has no effect. Reset Source: mod_g_rst_n
{0x3100+4i} WKUP_CTRL_MMR_CFG0_CLAIMREG_P0_R{i} (i=0..6)
  [31:0] CLAIMREG_P0_R{i} — Claim bits for Partition 0 Reset Source: mod_g_rst_n
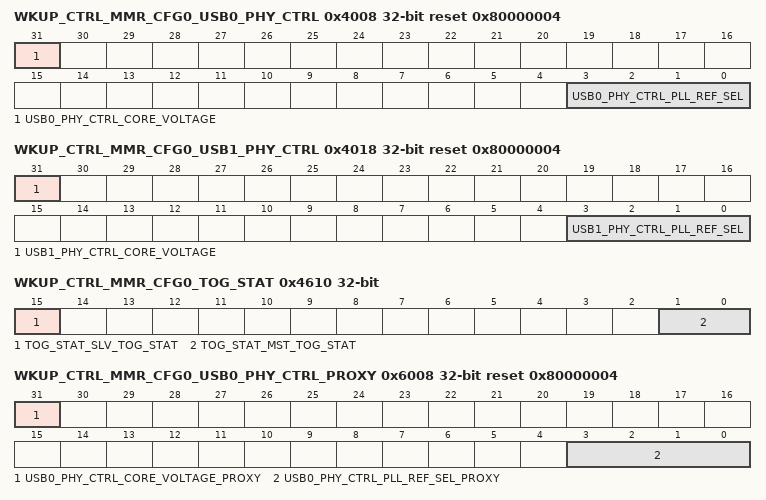
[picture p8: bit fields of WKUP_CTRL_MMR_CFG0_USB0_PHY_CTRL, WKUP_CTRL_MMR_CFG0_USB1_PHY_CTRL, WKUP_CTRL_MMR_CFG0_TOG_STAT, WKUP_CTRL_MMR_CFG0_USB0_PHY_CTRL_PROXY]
0x4008 WKUP_CTRL_MMR_CFG0_USB0_PHY_CTRL reset 0x80000004
  [31] USB0_PHY_CTRL_CORE_VOLTAGE — Selects the USB PHY Core Voltage0 - Core Voltage is 0.85V1 - Core Voltage is 0.75V/0.80V Reset Source: mod_g_rst_n
  [3:0] USB0_PHY_CTRL_PLL_REF_SEL — Indicates the frequency of the REF_CLOCK input used by the USB PLL. This value should be set to match the frequency of the USB0 input clock, as selected by the USB0_CLKSEL registerField values (others are reserved):4'b0000 - 9.6 MHz4'b0001 - 10 MHz4'b0010 - 12 MHz4'b0011 - 19.2 MHZ4'b0100 - 20 MHz4'b0101 - 24 MHz4'b0110 - 25 MHz4'b0111 - 26 MHz4'b1000 - 38.4 MHz4'b1001 - 40 MHz4'b1010 - 48 MHz4'b1011 - 50 MHz4'b1100 - 52 MHz Reset Source: mod_g_rst_n
0x4018 WKUP_CTRL_MMR_CFG0_USB1_PHY_CTRL reset 0x80000004
  [31] USB1_PHY_CTRL_CORE_VOLTAGE — Selects the USB PHY Core Voltage0 - Core Voltage is 0.85V1 - Core Voltage is 0.75V/0.80V Reset Source: mod_g_rst_n
  [3:0] USB1_PHY_CTRL_PLL_REF_SEL — Indicates the frequency of the REF_CLOCK input used by the USB PLL. This value should be set to match the frequency of the USB1 input clock, as selected by the USB1_CLKSEL registerField values (others are reserved):4'b0000 - 9.6 MHz4'b0001 - 10 MHz4'b0010 - 12 MHz4'b0011 - 19.2 MHZ4'b0100 - 20 MHz4'b0101 - 24 MHz4'b0110 - 25 MHz4'b0111 - 26 MHz4'b1000 - 38.4 MHz4'b1001 - 40 MHz4'b1010 - 48 MHz4'b1011 - 50 MHz4'b1100 - 52 MHz Reset Source: mod_g_rst_n
{0x41B4+4i} WKUP_CTRL_MMR_CFG0_SDIO{i}_CTRL (i=0..2)
  [4:0] SDIO{i}_CTRL_DRV_STR — Selects the SDIO drive strengthNote: Values other than the reset value may invalidate the datasheet timing parameters and therefore should not be used. Reset Source: mod_por_rst_n
0x4204 WKUP_CTRL_MMR_CFG0_WKUP_TIMER1_CTRL
  [8] WKUP_TIMER1_CTRL_CASCADE_EN — Activates cascading of TIMER1 to TIMER0 Reset Source: sys_por_rst_n
0x42E0 WKUP_CTRL_MMR_CFG0_WKUP_I2C0_CTRL
  [0] WKUP_I2C0_CTRL_HS_MCS_EN — HS Mode controller current source activate.When set, activates the current-source pull-up on the SCL output. Only one controller on the I2C bus should activate SCL current sourcing. Reset Source: mod_g_rst_n
0x4610 WKUP_CTRL_MMR_CFG0_TOG_STAT ro
  [15] TOG_STAT_SLV_TOG_STAT — Error Status of Target Timeout GasketsField values (others are reserved):1'b0 - No Error1'b1 - Error from mcu2dm timeout gasket MCU_TIMEOUT0 Reset Source: mod_g_rst_n
  [1:0] TOG_STAT_MST_TOG_STAT — Error Status of Target Timeout GasketsField values (others are reserved):2'b00 - No Error2'b01 - Error from dm2mcu WKUP_TIMEOUT1 gasket2'b10 - Error from dm2ws WKUP_TIMEOUT0 gasket2'b11 - Error from both dm2mcu and dm2ws WKUP_TIMEOUT1 and WKUP_TIMEOUT0 gaskets Reset Source: mod_g_rst_n
{0x5100+4i} WKUP_CTRL_MMR_CFG0_CLAIMREG_P1_R{i}_READONLY ro (i=0..12)
  [31:0] CLAIMREG_P1_R{i}_READONLY — Claim bits for Partition 1 Reset Source: mod_g_rst_n
0x6008 WKUP_CTRL_MMR_CFG0_USB0_PHY_CTRL_PROXY reset 0x80000004
  [31] USB0_PHY_CTRL_CORE_VOLTAGE_PROXY — Selects the USB PHY Core Voltage0 - Core Voltage is 0.85V1 - Core Voltage is 0.75V/0.80V Reset Source: mod_g_rst_n
  [3:0] USB0_PHY_CTRL_PLL_REF_SEL_PROXY — Indicates the frequency of the REF_CLOCK input used by the USB PLL. This value should be set to match the frequency of the USB0 input clock, as selected by the USB0_CLKSEL registerField values (others are reserved):4'b0000 - 9.6 MHz4'b0001 - 10 MHz4'b0010 - 12 MHz4'b0011 - 19.2 MHZ4'b0100 - 20 MHz4'b0101 - 24 MHz4'b0110 - 25 MHz4'b0111 - 26 MHz4'b1000 - 38.4 MHz4'b1001 - 40 MHz4'b1010 - 48 MHz4'b1011 - 50 MHz4'b1100 - 52 MHz Reset Source: mod_g_rst_n
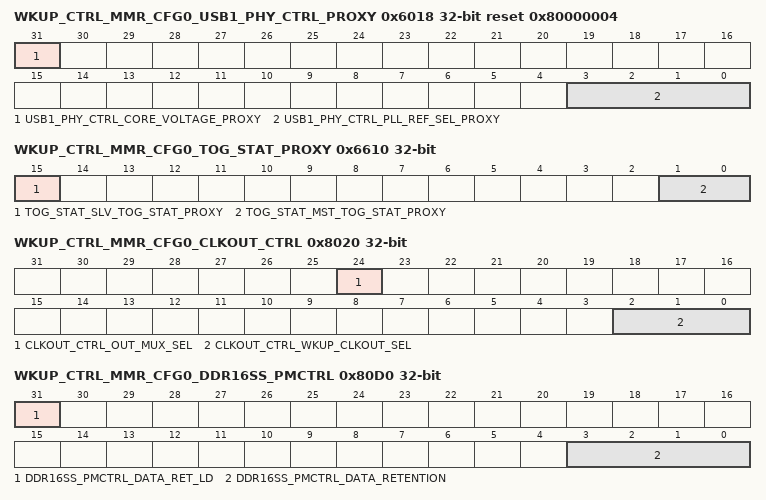
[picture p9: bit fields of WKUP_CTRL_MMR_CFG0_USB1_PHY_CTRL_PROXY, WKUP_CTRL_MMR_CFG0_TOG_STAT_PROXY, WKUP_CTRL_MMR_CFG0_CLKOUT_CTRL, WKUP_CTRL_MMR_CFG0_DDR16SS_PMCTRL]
0x6018 WKUP_CTRL_MMR_CFG0_USB1_PHY_CTRL_PROXY reset 0x80000004
  [31] USB1_PHY_CTRL_CORE_VOLTAGE_PROXY — Selects the USB PHY Core Voltage0 - Core Voltage is 0.85V1 - Core Voltage is 0.75V/0.80V Reset Source: mod_g_rst_n
  [3:0] USB1_PHY_CTRL_PLL_REF_SEL_PROXY — Indicates the frequency of the REF_CLOCK input used by the USB PLL. This value should be set to match the frequency of the USB1 input clock, as selected by the USB1_CLKSEL registerField values (others are reserved):4'b0000 - 9.6 MHz4'b0001 - 10 MHz4'b0010 - 12 MHz4'b0011 - 19.2 MHZ4'b0100 - 20 MHz4'b0101 - 24 MHz4'b0110 - 25 MHz4'b0111 - 26 MHz4'b1000 - 38.4 MHz4'b1001 - 40 MHz4'b1010 - 48 MHz4'b1011 - 50 MHz4'b1100 - 52 MHz Reset Source: mod_g_rst_n
{0x61B4+4i} WKUP_CTRL_MMR_CFG0_SDIO{i}_CTRL_PROXY (i=0..2)
  [4:0] SDIO{i}_CTRL_DRV_STR_PROXY — Selects the SDIO drive strengthNote: Values other than the reset value may invalidate the datasheet timing parameters and therefore should not be used. Reset Source: mod_por_rst_n
0x6204 WKUP_CTRL_MMR_CFG0_WKUP_TIMER1_CTRL_PROXY
  [8] WKUP_TIMER1_CTRL_CASCADE_EN_PROXY — Activates cascading of TIMER1 to TIMER0 Reset Source: sys_por_rst_n
0x62E0 WKUP_CTRL_MMR_CFG0_WKUP_I2C0_CTRL_PROXY
  [0] WKUP_I2C0_CTRL_HS_MCS_EN_PROXY — HS Mode controller current source activate.When set, activates the current-source pull-up on the SCL output. Only one controller on the I2C bus should activate SCL current sourcing. Reset Source: mod_g_rst_n
0x6610 WKUP_CTRL_MMR_CFG0_TOG_STAT_PROXY ro
  [15] TOG_STAT_SLV_TOG_STAT_PROXY — Error Status of Target Timeout GasketsField values (others are reserved):1'b0 - No Error1'b1 - Error from mcu2dm timeout gasket MCU_TIMEOUT0 Reset Source: mod_g_rst_n
  [1:0] TOG_STAT_MST_TOG_STAT_PROXY — Error Status of Target Timeout GasketsField values (others are reserved):2'b00 - No Error2'b01 - Error from dm2mcu WKUP_TIMEOUT1 gasket2'b10 - Error from dm2ws WKUP_TIMEOUT0 gasket2'b11 - Error from both dm2mcu and dm2ws WKUP_TIMEOUT1 and WKUP_TIMEOUT0 gaskets Reset Source: mod_g_rst_n
{0x7100+4i} WKUP_CTRL_MMR_CFG0_CLAIMREG_P1_R{i} (i=0..12)
  [31:0] CLAIMREG_P1_R{i} — Claim bits for Partition 1 Reset Source: mod_g_rst_n
0x8010 WKUP_CTRL_MMR_CFG0_WKUP_CLKSEL
  [0] WKUP_CLKSEL_CLK_SEL — Selects Clock Source for Wakeup Domain (Device Manager and Peripherals)Field values (others are reserved):1'b0 - CPU: MAIN_PLL15_HSDIV2_CLKOUT, Peripherals: MAIN_PLL15_HSDIV0_CLKOUT0 1'b1 - CPU and Peripherals: MCU_PLL0_HSDIV0_CKLOUT Reset Source: mod_g_rst_n
0x8020 WKUP_CTRL_MMR_CFG0_CLKOUT_CTRL
  [24] CLKOUT_CTRL_OUT_MUX_SEL — WKUP CLKOUT (Pin) pin output mux selection. HFOSC0_CLK is a direct output from the HFOSC0 Reset Source: mod_por_rst_n
  [2:0] CLKOUT_CTRL_WKUP_CLKOUT_SEL — Controls WKUP CLKOUT MUX for WKUP_CLKOUT0 PinField values (others are reserved):undefined - undefined3'b000 - DRIVE_LOWundefined - undefined3'b001 - LFOSC0_CLKOUT3'b010 - MAIN_PLL0_HSDIV2_CLKOUT3'b011 - MAIN_PLL1_HSDIV2_CLKOUT3'b100 - MAIN_PLL2_HSDIV9_CLKOUT3'b101 - DEVICE_CLKOUT_32K3'b110 - CLK_12M_RC3'b111 - HFOSC0_CLKOUT Reset Source: mod_por_rst_n
0x8030 WKUP_CTRL_MMR_CFG0_WKUP_GTC_CLKSEL reset 0x1
  [2:0] WKUP_GTC_CLKSEL_CLK_SEL — Selects the GTC timebase clock sourceField values (others are reserved):3'b000 - MAIN_PLL2_HSDIV5_CLKOUT3'b001 - MAIN_PLL0_HSDIV6_CLKOUT3'b010 - CPSW2G_CPTS_RFT_CLK3'b011 - Reserved '0'3'b100 - MCU_EXT_REFCLK03'b101 - EXT_REFCLK13'b110 - MCU_SYSCLK0undefined - undefined3'b111 - MAIN_SYSCLK0 Reset Source: mod_g_rst_n
0x803C WKUP_CTRL_MMR_CFG0_EFUSE_CLKSEL
  [0] EFUSE_CLKSEL_CLK_SEL — Selects the clock sourceField values (others are reserved):1'b0 - HFOSC0_CLKOUT1'b1 - MAIN_SYSCLK0/16 Reset Source: mod_por_rst_n
0x80D0 WKUP_CTRL_MMR_CFG0_DDR16SS_PMCTRL
  [31] DDR16SS_PMCTRL_DATA_RET_LD — Controls latching of the retention valueField values (others are reserved):1'b0 - Latch Closed1'b1 - Latch Open Reset Source: mcu_chip1_rst_n
  [3:0] DDR16SS_PMCTRL_DATA_RETENTION — DDR16SS Retention: This is a fault tolerant bit field 0x06 Asserts DDRSS 'data_retention' which will Hi-Z most of the phy output pins except for CKE/RESET# All others (Default 0) : data_retention is deasserted for normal DDR16SS OperationField values (others are reserved):4'b0110 - Retention Activated4'b0000 - Retention Deactivated Reset Source: mcu_chip1_rst_n
0x8190 WKUP_CTRL_MMR_CFG0_USB0_CLKSEL
  [0] USB0_CLKSEL_REFCLK_SEL — Selects the clock source for the USB0 ref_clk. Field values (others are reserved):1'b0 - HFOSC0_CLKOUT1'b1 - MAIN_PLL0_HSDIV8_CLKOUT Reset Source: mod_g_rst_n
0x8194 WKUP_CTRL_MMR_CFG0_USB1_CLKSEL
  [0] USB1_CLKSEL_REFCLK_SEL — Selects the clock source for the USB1 ref_clk. Field values (others are reserved):1'b0 - HFOSC0_CLKOUT1'b1 - MAIN_PLL0_HSDIV8_CLKOUT Reset Source: mod_g_rst_n
0x81B0 WKUP_CTRL_MMR_CFG0_WKUP_TIMER0_CLKSEL
  [2:0] WKUP_TIMER0_CLKSEL_CLK_SEL — Timer functional clock input select mux controlField values (others are reserved):3'b000 - HFOSC0_CLKOUT3'b001 - DM_CLK/2undefined - undefined3'b010 - CLK_12M_RC3'b011 - MCU_PLL0_HSDIV3_CLKOUT3'b100 - MCU_EXT_REFCLK0 (pin)3'b101 - DEVICE_CLKOUT_32K3'b110 - CPSW2G_CPTS_RFT_CLK3'b111 - CLK_32K_RC Reset Source: sys_por_rst_n
0x81B4 WKUP_CTRL_MMR_CFG0_WKUP_TIMER1_CLKSEL
  [2:0] WKUP_TIMER1_CLKSEL_CLK_SEL — Timer functional clock input select mux controlField values (others are reserved):3'b000 - HFOSC0_CLKOUT3'b001 - DM_CLK/2undefined - undefined3'b010 - CLK_12M_RC3'b011 - MCU_PLL0_HSDIV3_CLKOUT3'b100 - MCU_EXT_REFCLK0 (pin)3'b101 - DEVICE_CLKOUT_32K3'b110 - CPSW2G_CPTS_RFT_CLK3'b111 - CLK_32K_RC Reset Source: sys_por_rst_n
0x8340 WKUP_CTRL_MMR_CFG0_WKUP_WWD0_CTRL
  [3:0] WKUP_WWD0_CTRL_WWD_STOP — Controls Clocks to the WWD Watchdog CounterField values (others are reserved):4'b0000 - WWD Counter Running4'b1010 - WWD Counter Stopped Reset Source: mod_g_rst_n
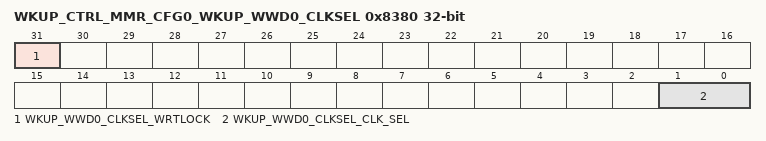
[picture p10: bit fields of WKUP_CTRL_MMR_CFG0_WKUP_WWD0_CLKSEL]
0x8380 WKUP_CTRL_MMR_CFG0_WKUP_WWD0_CLKSEL
  [31] WKUP_WWD0_CLKSEL_WRTLOCK — When set, locks WWD0_CLKSEL from further writes until the next module reset. Reset Source: mod_g_rst_n
  [1:0] WKUP_WWD0_CLKSEL_CLK_SEL — Windowed watchdog timer functional clock input select mux controlField values (others are reserved):2'b00 - HFOSC0_CLKOUT2'b01 - DEVICE_CLKOUT_32K2'b10 - CLK_12M_RC2'b11 - CLK_32K Reset Source: mod_g_rst_n
0x8600 WKUP_CTRL_MMR_CFG0_WKUP_RTC_CLKSEL
  [0] WKUP_RTC_CLKSEL_CLK_SEL — Selects the source of the RTC functional clockField values (others are reserved):1'b0 - DEVICE_CLKOUT_32K1'b1 - CLK_32K_RC Reset Source: mod_por_rst_n
{0x9100+4i} WKUP_CTRL_MMR_CFG0_CLAIMREG_P2_R{i}_READONLY ro (i=0..12)
  [31:0] CLAIMREG_P2_R{i}_READONLY — Claim bits for Partition 2 Reset Source: mod_g_rst_n
0xA010 WKUP_CTRL_MMR_CFG0_WKUP_CLKSEL_PROXY
  [0] WKUP_CLKSEL_CLK_SEL_PROXY — Selects Clock Source for Wakeup Domain (Device Manager and Peripherals)Field values (others are reserved):1'b0 - CPU: MAIN_PLL15_HSDIV2_CLKOUT, Peripherals: MAIN_PLL15_HSDIV0_CLKOUT0 1'b1 - CPU and Peripherals: MCU_PLL0_HSDIV0_CKLOUT Reset Source: mod_g_rst_n
